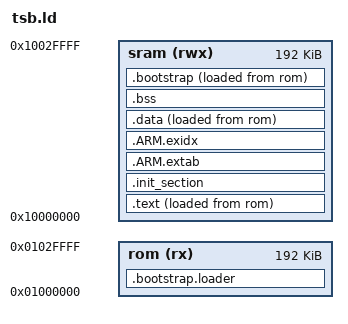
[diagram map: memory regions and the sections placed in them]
/**
 * Copyright (c) 2015 Google Inc.
 * All rights reserved.
 *
 * Redistribution and use in source and binary forms, with or without
 * modification, are permitted provided that the following conditions are met:
 * 1. Redistributions of source code must retain the above copyright notice,
 * this list of conditions and the following disclaimer.
 * 2. Redistributions in binary form must reproduce the above copyright notice,
 * this list of conditions and the following disclaimer in the documentation
 * and/or other materials provided with the distribution.
 * 3. Neither the name of the copyright holder nor the names of its
 * contributors may be used to endorse or promote products derived from this
 * software without specific prior written permission.
 *
 * THIS SOFTWARE IS PROVIDED BY THE COPYRIGHT HOLDERS AND CONTRIBUTORS "AS IS"
 * AND ANY EXPRESS OR IMPLIED WARRANTIES, INCLUDING, BUT NOT LIMITED TO,
 * THE IMPLIED WARRANTIES OF MERCHANTABILITY AND FITNESS FOR A PARTICULAR
 * PURPOSE ARE DISCLAIMED. IN NO EVENT SHALL THE COPYRIGHT HOLDER OR
 * CONTRIBUTORS BE LIABLE FOR ANY DIRECT, INDIRECT, INCIDENTAL, SPECIAL,
 * EXEMPLARY, OR CONSEQUENTIAL DAMAGES (INCLUDING, BUT NOT LIMITED TO,
 * PROCUREMENT OF SUBSTITUTE GOODS OR SERVICES; LOSS OF USE, DATA, OR PROFITS;
 * OR BUSINESS INTERRUPTION) HOWEVER CAUSED AND ON ANY THEORY OF LIABILITY,
 * WHETHER IN CONTRACT, STRICT LIABILITY, OR TORT (INCLUDING NEGLIGENCE OR
 * OTHERWISE) ARISING IN ANY WAY OUT OF THE USE OF THIS SOFTWARE, EVEN IF
 * ADVISED OF THE POSSIBILITY OF SUCH DAMAGE.
 */

MEMORY
{
    rom  (rx)  : ORIGIN = 0x01000000, LENGTH = 192K
    sram (rwx) : ORIGIN = 0x10000000, LENGTH = 192K
}


OUTPUT_ARCH(arm)
EXTERN(_vectors)
ENTRY(_spi_stext)
SECTIONS
{
    .bootstrap.loader : {
        KEEP(*(.bootstrap.vector))
        KEEP(*(.bootstrap.loader))
        _spi_stext = ABSOLUTE(.);
    } > rom

    .text : {
        _stext = ABSOLUTE(.);
        *(.vectors)
        KEEP(*(.text))
        *(.text.*)
        *(.fixup)
        *(.gnu.warning)
        *(.rodata .rodata.*)
        *(.gnu.linkonce.t.*)
        *(.glue_7)
        *(.glue_7t)
        *(.got)
        *(.gcc_except_table)
        *(.gnu.linkonce.r.*)
        _etext = ABSOLUTE(.);
    } > sram AT > rom

    _stext_lma = LOADADDR(.text);
    _text_size = SIZEOF(.text);

    .init_section : {
        _sinit = ABSOLUTE(.);
        *(.init_array .init_array.*)
        _einit = ABSOLUTE(.);
    } > sram

    .ARM.extab : {
        *(.ARM.extab*)
    } > sram

    __exidx_start = ABSOLUTE(.);
    .ARM.exidx : {
        *(.ARM.exidx*)
    } > sram
    __exidx_end = ABSOLUTE(.);

    _eronly = ABSOLUTE(.);

    .data ALIGN(0x4) : {
        _sdata = ABSOLUTE(.);
        *(.data .data.*)
        *(.gnu.linkonce.d.*)
        CONSTRUCTORS
        _edata = ABSOLUTE(.);
    } > sram AT > rom

    _sdata_lma = LOADADDR(.data);

    .bss : {
        _sbss = ABSOLUTE(.);
        *(.bss .bss.*)
        *(.gnu.linkonce.b.*)
        *(COMMON)
        _ebss = ABSOLUTE(.);
    } > sram

    .bootstrap : {
        *(.bootstrap)
    } > sram AT > rom

    _bootstrap_lma = LOADADDR(.bootstrap);
    _bootstrap_vma = ADDR(.bootstrap);
    _bootstrap_size = SIZEOF(.bootstrap);


    /* Stabs debugging sections. */
    .stab 0 : { *(.stab) }
    .stabstr 0 : { *(.stabstr) }
    .stab.excl 0 : { *(.stab.excl) }
    .stab.exclstr 0 : { *(.stab.exclstr) }
    .stab.index 0 : { *(.stab.index) }
    .stab.indexstr 0 : { *(.stab.indexstr) }
    .comment 0 : { *(.comment) }
    .debug_abbrev 0 : { *(.debug_abbrev) }
    .debug_info 0 : { *(.debug_info) }
    .debug_line 0 : { *(.debug_line) }
    .debug_pubnames 0 : { *(.debug_pubnames) }
    .debug_aranges 0 : { *(.debug_aranges) }
}
